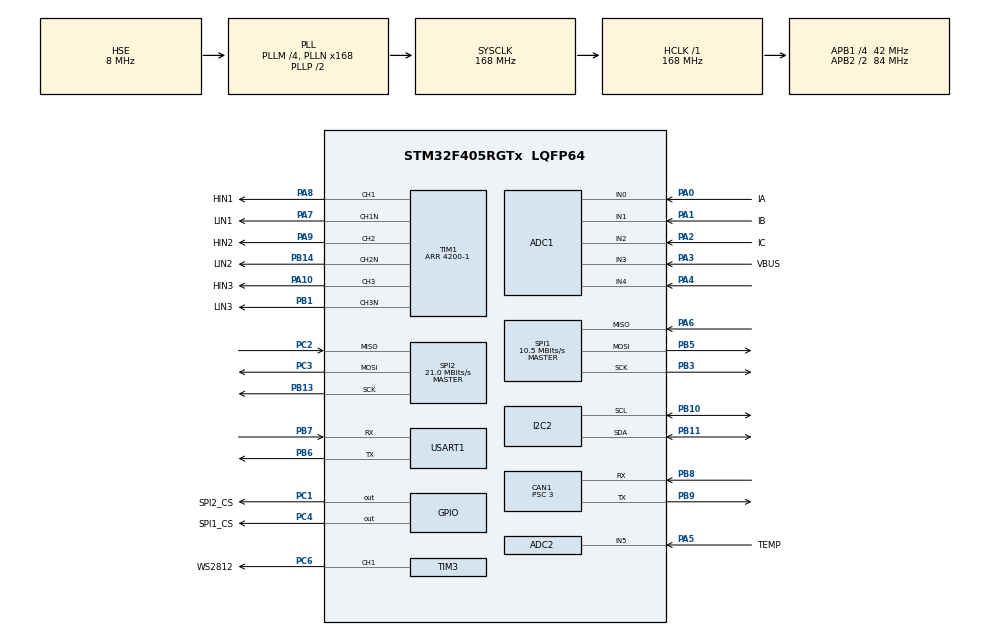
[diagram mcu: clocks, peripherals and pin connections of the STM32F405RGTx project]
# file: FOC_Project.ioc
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ADC1.Channel-0\#ChannelRegularConversion=ADC_CHANNEL_0
ADC1.Channel-1\#ChannelInjectedConversion=ADC_CHANNEL_0
ADC1.Channel-2\#ChannelInjectedConversion=ADC_CHANNEL_0
ADC1.Channel-3\#ChannelInjectedConversion=ADC_CHANNEL_0
ADC1.Channel-4\#ChannelInjectedConversion=ADC_CHANNEL_0
ADC1.ClockPrescaler=ADC_CLOCK_SYNC_PCLK_DIV6
ADC1.ContinuousConvMode=ENABLE
ADC1.InjNumberOfConversion=4
ADC1.InjectedOffset-1\#ChannelInjectedConversion=0
ADC1.InjectedOffset-2\#ChannelInjectedConversion=0
ADC1.InjectedOffset-3\#ChannelInjectedConversion=0
ADC1.InjectedOffset-4\#ChannelInjectedConversion=0
ADC1.InjectedRank-1\#ChannelInjectedConversion=1
ADC1.InjectedRank-2\#ChannelInjectedConversion=2
ADC1.InjectedRank-3\#ChannelInjectedConversion=3
ADC1.InjectedRank-4\#ChannelInjectedConversion=4
ADC1.NbrOfConversionFlag=1
ADC1.Rank-0\#ChannelRegularConversion=1
ADC1.SamplingTime-0\#ChannelRegularConversion=ADC_SAMPLETIME_3CYCLES
ADC1.SamplingTime-1\#ChannelInjectedConversion=ADC_SAMPLETIME_3CYCLES
ADC1.SamplingTime-2\#ChannelInjectedConversion=ADC_SAMPLETIME_3CYCLES
ADC1.SamplingTime-3\#ChannelInjectedConversion=ADC_SAMPLETIME_3CYCLES
ADC1.SamplingTime-4\#ChannelInjectedConversion=ADC_SAMPLETIME_3CYCLES
ADC1.ScanConvMode=ENABLE
ADC1.master=1
ADC2.Channel-0\#ChannelRegularConversion=ADC_CHANNEL_5
ADC2.ClockPrescaler=ADC_CLOCK_SYNC_PCLK_DIV6
ADC2.NbrOfConversionFlag=1
ADC2.Rank-0\#ChannelRegularConversion=1
ADC2.SamplingTime-0\#ChannelRegularConversion=ADC_SAMPLETIME_3CYCLES
CAN1.BS1=CAN_BS1_11TQ
CAN1.BS2=CAN_BS2_2TQ
CAN1.CalculateBaudRate=1000000
CAN1.CalculateTimeBit=1000
CAN1.CalculateTimeQuantum=71.42857142857143
CAN1.Prescaler=3
Dma.Request0=SPI1_RX
Dma.Request1=SPI1_TX
Dma.Request2=USART1_RX
Dma.Request3=USART1_TX
Dma.Request4=TIM3_CH1/TRIG
Dma.SPI1_RX.0.Direction=DMA_PERIPH_TO_MEMORY
Dma.SPI1_RX.0.FIFOMode=DMA_FIFOMODE_DISABLE
Dma.SPI1_RX.0.Instance=DMA2_Stream0
Dma.SPI1_RX.0.MemDataAlignment=DMA_MDATAALIGN_BYTE
Dma.SPI1_RX.0.MemInc=DMA_MINC_ENABLE
Dma.SPI1_RX.0.Mode=DMA_NORMAL
Dma.SPI1_RX.0.PeriphDataAlignment=DMA_PDATAALIGN_BYTE
Dma.SPI1_RX.0.PeriphInc=DMA_PINC_DISABLE
Dma.SPI1_RX.0.Priority=DMA_PRIORITY_HIGH
Dma.SPI1_TX.1.Direction=DMA_MEMORY_TO_PERIPH
Dma.SPI1_TX.1.FIFOMode=DMA_FIFOMODE_DISABLE
Dma.SPI1_TX.1.Instance=DMA2_Stream3
Dma.SPI1_TX.1.MemDataAlignment=DMA_MDATAALIGN_BYTE
Dma.SPI1_TX.1.MemInc=DMA_MINC_ENABLE
Dma.SPI1_TX.1.Mode=DMA_NORMAL
Dma.SPI1_TX.1.PeriphDataAlignment=DMA_PDATAALIGN_BYTE
Dma.SPI1_TX.1.PeriphInc=DMA_PINC_DISABLE
Dma.SPI1_TX.1.Priority=DMA_PRIORITY_HIGH
Dma.TIM3_CH1/TRIG.4.Direction=DMA_PERIPH_TO_MEMORY
Dma.TIM3_CH1/TRIG.4.FIFOMode=DMA_FIFOMODE_DISABLE
Dma.TIM3_CH1/TRIG.4.Instance=DMA1_Stream4
Dma.TIM3_CH1/TRIG.4.MemDataAlignment=DMA_MDATAALIGN_HALFWORD
Dma.TIM3_CH1/TRIG.4.MemInc=DMA_MINC_ENABLE
Dma.TIM3_CH1/TRIG.4.Mode=DMA_NORMAL
Dma.TIM3_CH1/TRIG.4.PeriphDataAlignment=DMA_PDATAALIGN_HALFWORD
Dma.TIM3_CH1/TRIG.4.PeriphInc=DMA_PINC_DISABLE
Dma.TIM3_CH1/TRIG.4.Priority=DMA_PRIORITY_LOW
Dma.USART1_RX.2.Direction=DMA_PERIPH_TO_MEMORY
Dma.USART1_RX.2.FIFOMode=DMA_FIFOMODE_DISABLE
Dma.USART1_RX.2.Instance=DMA2_Stream2
Dma.USART1_RX.2.MemDataAlignment=DMA_MDATAALIGN_BYTE
Dma.USART1_RX.2.MemInc=DMA_MINC_ENABLE
Dma.USART1_RX.2.Mode=DMA_NORMAL
Dma.USART1_RX.2.PeriphDataAlignment=DMA_PDATAALIGN_BYTE
Dma.USART1_RX.2.PeriphInc=DMA_PINC_DISABLE
Dma.USART1_RX.2.Priority=DMA_PRIORITY_LOW
Dma.USART1_TX.3.Direction=DMA_MEMORY_TO_PERIPH
Dma.USART1_TX.3.FIFOMode=DMA_FIFOMODE_DISABLE
Dma.USART1_TX.3.Instance=DMA2_Stream7
Dma.USART1_TX.3.MemDataAlignment=DMA_MDATAALIGN_BYTE
Dma.USART1_TX.3.MemInc=DMA_MINC_ENABLE
Dma.USART1_TX.3.Mode=DMA_NORMAL
Dma.USART1_TX.3.PeriphDataAlignment=DMA_PDATAALIGN_BYTE
Dma.USART1_TX.3.PeriphInc=DMA_PINC_DISABLE
Dma.USART1_TX.3.Priority=DMA_PRIORITY_LOW
FREERTOS.Tasks01=defaultTask,24,1024,StartDefaultTask,Default,NULL,Dynamic,NULL,NULL
FREERTOS.configTOTAL_HEAP_SIZE=65535
Mcu.Family=STM32F4
Mcu.Name=STM32F405RGTx
Mcu.Package=LQFP64
NVIC.ADC_IRQn=true\:5\:0\:false\:false\:true\:true\:true\:true\:true
NVIC.CAN1_RX0_IRQn=true\:6\:0\:true\:false\:true\:true\:true\:true\:true
NVIC.CAN1_RX1_IRQn=true\:6\:0\:true\:false\:true\:true\:true\:true\:true
NVIC.CAN1_SCE_IRQn=true\:6\:0\:true\:false\:true\:true\:true\:true\:true
NVIC.CAN1_TX_IRQn=true\:6\:0\:true\:false\:true\:true\:true\:true\:true
NVIC.DMA1_Stream4_IRQn=true\:5\:0\:false\:false\:true\:true\:false\:true\:true
NVIC.DMA2_Stream0_IRQn=true\:5\:0\:false\:false\:true\:true\:false\:true\:true
NVIC.DMA2_Stream2_IRQn=true\:5\:0\:false\:false\:true\:true\:false\:true\:true
NVIC.DMA2_Stream3_IRQn=true\:5\:0\:false\:false\:true\:true\:false\:true\:true
NVIC.DMA2_Stream7_IRQn=true\:5\:0\:false\:false\:true\:true\:false\:true\:true
NVIC.PriorityGroup=NVIC_PRIORITYGROUP_4
NVIC.TIM1_TRG_COM_TIM11_IRQn=true\:15\:0\:true\:false\:true\:true\:true\:true\:true
NVIC.TIM2_IRQn=true\:5\:0\:false\:false\:true\:true\:true\:true\:true
NVIC.TimeBase=TIM1_TRG_COM_TIM11_IRQn
NVIC.TimeBaseIP=TIM11
NVIC.USART1_IRQn=true\:7\:0\:true\:false\:true\:true\:false\:true\:true
PA0-WKUP.GPIO_Label=IA
PA0-WKUP.Signal=ADCx_IN0
PA1.GPIO_Label=IB
PA1.Signal=ADCx_IN1
PA10.GPIO_Label=HIN3
PA10.Signal=S_TIM1_CH3
PA13.Mode=Serial_Wire
PA13.Signal=SYS_JTMS-SWDIO
PA14.Mode=Serial_Wire
PA14.Signal=SYS_JTCK-SWCLK
PA2.GPIO_Label=IC
PA2.Signal=ADCx_IN2
PA3.GPIO_Label=VBUS
PA3.Signal=ADCx_IN3
PA4.Signal=ADCx_IN4
PA5.GPIO_Label=TEMP
PA5.Signal=ADCx_IN5
PA6.Mode=Full_Duplex_Master
PA6.Signal=SPI1_MISO
PA7.GPIO_Label=LIN1
PA7.Mode=PWM Generation1 CH1 CH1N
PA7.Signal=TIM1_CH1N
PA8.GPIO_Label=HIN1
PA8.Signal=S_TIM1_CH1
PA9.GPIO_Label=HIN2
PA9.Signal=S_TIM1_CH2
PB1.GPIO_Label=LIN3
PB1.Mode=PWM Generation3 CH3 CH3N
PB1.Signal=TIM1_CH3N
PB10.Mode=I2C
PB10.Signal=I2C2_SCL
PB11.Mode=I2C
PB11.Signal=I2C2_SDA
PB13.Mode=Full_Duplex_Master
PB13.Signal=SPI2_SCK
PB14.GPIO_Label=LIN2
PB14.Mode=PWM Generation2 CH2 CH2N
PB14.Signal=TIM1_CH2N
PB3.Mode=Full_Duplex_Master
PB3.Signal=SPI1_SCK
PB5.Mode=Full_Duplex_Master
PB5.Signal=SPI1_MOSI
PB6.GPIO_PuPd=GPIO_PULLDOWN
PB6.Mode=Asynchronous
PB6.Signal=USART1_TX
PB7.GPIO_PuPd=GPIO_PULLDOWN
PB7.Mode=Asynchronous
PB7.Signal=USART1_RX
PB8.Mode=CAN_Activate
PB8.Signal=CAN1_RX
PB9.Mode=CAN_Activate
PB9.Signal=CAN1_TX
PC1.GPIO_Label=SPI2_CS
PC1.Signal=GPIO_Output
PC2.Mode=Full_Duplex_Master
PC2.Signal=SPI2_MISO
PC3.Mode=Full_Duplex_Master
PC3.Signal=SPI2_MOSI
PC4.GPIO_Label=SPI1_CS
PC4.GPIO_Speed=GPIO_SPEED_FREQ_VERY_HIGH
PC4.Signal=GPIO_Output
PC6.GPIO_Label=WS2812
PC6.GPIO_Speed=GPIO_SPEED_FREQ_HIGH
PC6.Signal=S_TIM3_CH1
PH0-OSC_IN.Mode=HSE-External-Oscillator
PH0-OSC_IN.Signal=RCC_OSC_IN
PH1-OSC_OUT.Mode=HSE-External-Oscillator
PH1-OSC_OUT.Signal=RCC_OSC_OUT
ProjectManager.HeapSize=0x200
ProjectManager.StackSize=0x400
ProjectManager.TargetToolchain=CMake
RCC.48MHZClocksFreq_Value=84000000
RCC.AHBFreq_Value=168000000
RCC.APB1CLKDivider=RCC_HCLK_DIV4
RCC.APB1Freq_Value=42000000
RCC.APB1TimFreq_Value=84000000
RCC.APB2CLKDivider=RCC_HCLK_DIV2
RCC.APB2Freq_Value=84000000
RCC.APB2TimFreq_Value=168000000
RCC.CortexFreq_Value=168000000
RCC.HCLKFreq_Value=168000000
RCC.HSE_VALUE=8000000
RCC.HSI_VALUE=16000000
RCC.LSE_VALUE=32768
RCC.PLLM=4
RCC.PLLN=168
RCC.PLLSourceVirtual=RCC_PLLSOURCE_HSE
RCC.SYSCLKFreq_VALUE=168000000
RCC.SYSCLKSource=RCC_SYSCLKSOURCE_PLLCLK
RCC.VCOOutputFreq_Value=336000000
SH.ADCx_IN0.0=ADC1_IN0,IN0
SH.ADCx_IN1.0=ADC1_IN1,IN1
SH.ADCx_IN2.0=ADC1_IN2,IN2
SH.ADCx_IN3.0=ADC1_IN3,IN3
SH.ADCx_IN4.0=ADC1_IN4,IN4
SH.ADCx_IN5.0=ADC2_IN5,IN5
SH.S_TIM1_CH1.0=TIM1_CH1,PWM Generation1 CH1 CH1N
SH.S_TIM1_CH2.0=TIM1_CH2,PWM Generation2 CH2 CH2N
SH.S_TIM1_CH3.0=TIM1_CH3,PWM Generation3 CH3 CH3N
SH.S_TIM3_CH1.0=TIM3_CH1,PWM Generation1 CH1
SPI1.BaudRatePrescaler=SPI_BAUDRATEPRESCALER_8
SPI1.CLKPhase=SPI_PHASE_2EDGE
SPI1.CalculateBaudRate=10.5 MBits/s
SPI1.Direction=SPI_DIRECTION_2LINES
SPI1.Mode=SPI_MODE_MASTER
SPI1.VirtualType=VM_MASTER
SPI2.CalculateBaudRate=21.0 MBits/s
SPI2.Direction=SPI_DIRECTION_2LINES
SPI2.Mode=SPI_MODE_MASTER
SPI2.VirtualType=VM_MASTER
STMicroelectronics.X-CUBE-ALGOBUILD.1.4.0.LibraryCcDSPOoLibraryJjDSPOoLibrary=true
TIM1.AutoReloadPreload=TIM_AUTORELOAD_PRELOAD_ENABLE
TIM1.Channel-PWM\ Generation1\ CH1\ CH1N=TIM_CHANNEL_1
TIM1.Channel-PWM\ Generation2\ CH2\ CH2N=TIM_CHANNEL_2
TIM1.Channel-PWM\ Generation3\ CH3\ CH3N=TIM_CHANNEL_3
TIM1.Channel-PWM\ Generation4\ No\ Output=TIM_CHANNEL_4
TIM1.CounterMode=TIM_COUNTERMODE_CENTERALIGNED1
TIM1.LockLevel=TIM_LOCKLEVEL_1
TIM1.Period=4200-1
TIM1.TIM_MasterOutputTrigger=TIM_TRGO_UPDATE
TIM2.AutoReloadPreload=TIM_AUTORELOAD_PRELOAD_ENABLE
TIM2.Period=10000-1
TIM2.Prescaler=168-1
TIM3.Channel-PWM\ Generation1\ CH1=TIM_CHANNEL_1
TIM3.Period=105-1
USART1.VirtualMode=VM_ASYNC
VP_FREERTOS_VS_CMSIS_V2.Mode=CMSIS_V2
VP_STMicroelectronics.X-CUBE-ALGOBUILD_VS_DSPOoLibraryJjLibrary_1.4.0_1.4.0.Mode=DSPOoLibraryJjLibrary
VP_SYS_VS_tim11.Mode=TIM11
VP_TIM1_VS_no_output4.Mode=PWM Generation4 No Output
VP_TIM2_VS_ClockSourceINT.Mode=Internal
VP_TIM3_VS_ClockSourceINT.Mode=Internal
board=custom

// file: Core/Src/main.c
/* USER CODE BEGIN Header */
/**
  ******************************************************************************
  * @file           : main.c
  * @brief          : Main program body
  ******************************************************************************
  * @attention
  *
  * Copyright (c) 2026 STMicroelectronics.
  * All rights reserved.
  *
  * This software is licensed under terms that can be found in the LICENSE file
  * in the root directory of this software component.
  * If no LICENSE file comes with this software, it is provided AS-IS.
  *
  ******************************************************************************
  */
/* USER CODE END Header */
#include "main.h"
#include "cmsis_os.h"
#include "adc.h"
#include "can.h"
#include "dma.h"
#include "i2c.h"
#include "spi.h"
#include "tim.h"
#include "usart.h"
#include "gpio.h"

void SystemClock_Config(void);
void MX_FREERTOS_Init(void);

int main(void)
{

  /* MCU Configuration--------------------------------------------------------*/

  /* Reset of all peripherals, Initializes the Flash interface and the Systick. */
  HAL_Init();

  /* Configure the system clock */
  SystemClock_Config();

  /* Initialize all configured peripherals */
  MX_GPIO_Init();
  MX_DMA_Init();
  MX_CAN1_Init();
  MX_I2C2_Init();
  MX_SPI1_Init();
  MX_SPI2_Init();
  MX_USART1_UART_Init();
  MX_TIM1_Init();
  MX_TIM2_Init();
  MX_TIM3_Init();
  MX_ADC1_Init();
  MX_ADC2_Init();

  /* Init scheduler */
  osKernelInitialize();  /* Call init function for freertos objects (in cmsis_os2.c) */
  MX_FREERTOS_Init();

  /* Start scheduler */
  osKernelStart();

  /* We should never get here as control is now taken by the scheduler */

  /* Infinite loop */
  while (1)
  {

  }
}

void SystemClock_Config(void)
{
  RCC_OscInitTypeDef RCC_OscInitStruct = {0};
  RCC_ClkInitTypeDef RCC_ClkInitStruct = {0};

  /** Configure the main internal regulator output voltage
  */
  __HAL_RCC_PWR_CLK_ENABLE();
  __HAL_PWR_VOLTAGESCALING_CONFIG(PWR_REGULATOR_VOLTAGE_SCALE1);

  /** Initializes the RCC Oscillators according to the specified parameters
  * in the RCC_OscInitTypeDef structure.
  */
  RCC_OscInitStruct.OscillatorType = RCC_OSCILLATORTYPE_HSE;
  RCC_OscInitStruct.HSEState = RCC_HSE_ON;
  RCC_OscInitStruct.PLL.PLLState = RCC_PLL_ON;
  RCC_OscInitStruct.PLL.PLLSource = RCC_PLLSOURCE_HSE;
  RCC_OscInitStruct.PLL.PLLM = 4;
  RCC_OscInitStruct.PLL.PLLN = 168;
  RCC_OscInitStruct.PLL.PLLP = RCC_PLLP_DIV2;
  RCC_OscInitStruct.PLL.PLLQ = 4;
  if (HAL_RCC_OscConfig(&RCC_OscInitStruct) != HAL_OK)
  {
    Error_Handler();
  }

  /** Initializes the CPU, AHB and APB buses clocks
  */
  RCC_ClkInitStruct.ClockType = RCC_CLOCKTYPE_HCLK|RCC_CLOCKTYPE_SYSCLK
                              |RCC_CLOCKTYPE_PCLK1|RCC_CLOCKTYPE_PCLK2;
  RCC_ClkInitStruct.SYSCLKSource = RCC_SYSCLKSOURCE_PLLCLK;
  RCC_ClkInitStruct.AHBCLKDivider = RCC_SYSCLK_DIV1;
  RCC_ClkInitStruct.APB1CLKDivider = RCC_HCLK_DIV4;
  RCC_ClkInitStruct.APB2CLKDivider = RCC_HCLK_DIV2;

  if (HAL_RCC_ClockConfig(&RCC_ClkInitStruct, FLASH_LATENCY_5) != HAL_OK)
  {
    Error_Handler();
  }
}

void HAL_TIM_PeriodElapsedCallback(TIM_HandleTypeDef *htim)
{
  if (htim->Instance == TIM11)
  {
    HAL_IncTick();
  }
}

void Error_Handler(void)
{
  __disable_irq();
  while (1)
  {
  }
}

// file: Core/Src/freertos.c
/* USER CODE BEGIN Header */
/**
  ******************************************************************************
  * File Name          : freertos.c
  * Description        : Code for freertos applications
  ******************************************************************************
  * @attention
  *
  * Copyright (c) 2026 STMicroelectronics.
  * All rights reserved.
  *
  * This software is licensed under terms that can be found in the LICENSE file
  * in the root directory of this software component.
  * If no LICENSE file comes with this software, it is provided AS-IS.
  *
  ******************************************************************************
  */
/* USER CODE END Header */

#include "FreeRTOS.h"
#include "task.h"
#include "main.h"
#include "cmsis_os.h"
#include "user_application.h"

/* Definitions for defaultTask */
osThreadId_t defaultTaskHandle;
const osThreadAttr_t defaultTask_attributes = {
  .name = "defaultTask",
  .stack_size = 1024 * 4,
  .priority = (osPriority_t) osPriorityNormal,
};

void StartDefaultTask(void *argument);

void MX_FREERTOS_Init(void); /* (MISRA C 2004 rule 8.1) */

void MX_FREERTOS_Init(void) {

  /* Create the thread(s) */
  /* creation of defaultTask */
  defaultTaskHandle = osThreadNew(StartDefaultTask, NULL, &defaultTask_attributes);

}

void StartDefaultTask(void *argument)
{
  /* USER CODE BEGIN StartDefaultTask */
  user_app();
  /* Infinite loop */
  for(;;)
  {
    osDelay(1);
  }
  /* USER CODE END StartDefaultTask */
}
